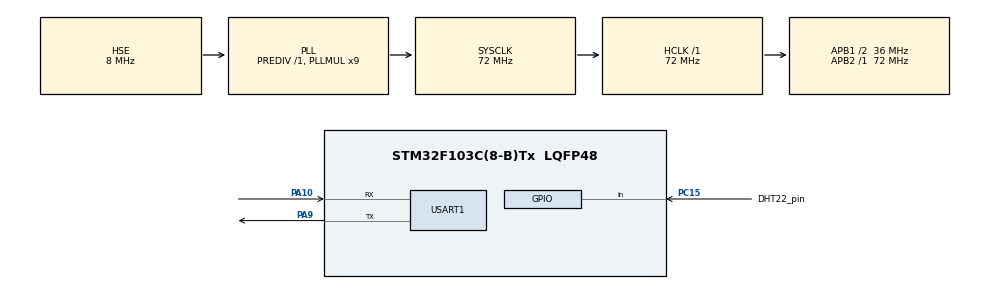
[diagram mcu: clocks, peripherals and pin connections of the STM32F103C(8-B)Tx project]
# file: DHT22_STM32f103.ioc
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Mcu.Family=STM32F1
Mcu.Name=STM32F103C(8-B)Tx
Mcu.Package=LQFP48
NVIC.PriorityGroup=NVIC_PRIORITYGROUP_4
PA10.Mode=Asynchronous
PA10.Signal=USART1_RX
PA13.Mode=Serial_Wire
PA13.Signal=SYS_JTMS-SWDIO
PA14.Mode=Serial_Wire
PA14.Signal=SYS_JTCK-SWCLK
PA9.Mode=Asynchronous
PA9.Signal=USART1_TX
PC15-OSC32_OUT.GPIO_Label=DHT22_pin
PC15-OSC32_OUT.Signal=GPIO_Input
PD0-OSC_IN.Mode=HSE-External-Oscillator
PD0-OSC_IN.Signal=RCC_OSC_IN
PD1-OSC_OUT.Mode=HSE-External-Oscillator
PD1-OSC_OUT.Signal=RCC_OSC_OUT
ProjectManager.HeapSize=0x200
ProjectManager.StackSize=0x400
ProjectManager.TargetToolchain=MDK-ARM V5
RCC.AHBFreq_Value=72000000
RCC.APB1CLKDivider=RCC_HCLK_DIV2
RCC.APB1Freq_Value=36000000
RCC.APB1TimFreq_Value=72000000
RCC.APB2Freq_Value=72000000
RCC.APB2TimFreq_Value=72000000
RCC.HCLKFreq_Value=72000000
RCC.PLLMUL=RCC_PLL_MUL9
RCC.PLLSourceVirtual=RCC_PLLSOURCE_HSE
RCC.SYSCLKFreq_VALUE=72000000
RCC.SYSCLKSource=RCC_SYSCLKSOURCE_PLLCLK
RCC.USBFreq_Value=72000000
TIM1.Period=0xffff
TIM1.Prescaler=72-1
USART1.VirtualMode=VM_ASYNC
VP_TIM1_VS_ClockSourceINT.Mode=Internal
board=custom

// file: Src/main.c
/* USER CODE BEGIN Header */
/**
  ******************************************************************************
  * @file           : main.c
  * @brief          : Main program body
  ******************************************************************************
  ** This notice applies to any and all portions of this file
  * that are not between comment pairs USER CODE BEGIN and
  * USER CODE END. Other portions of this file, whether
  * inserted by the user or by software development tools
  * are owned by their respective copyright owners.
  *
  * COPYRIGHT(c) 2020 STMicroelectronics
  *
  * Redistribution and use in source and binary forms, with or without modification,
  * are permitted provided that the following conditions are met:
  *   1. Redistributions of source code must retain the above copyright notice,
  *      this list of conditions and the following disclaimer.
  *   2. Redistributions in binary form must reproduce the above copyright notice,
  *      this list of conditions and the following disclaimer in the documentation
  *      and/or other materials provided with the distribution.
  *   3. Neither the name of STMicroelectronics nor the names of its contributors
  *      may be used to endorse or promote products derived from this software
  *      without specific prior written permission.
  *
  * THIS SOFTWARE IS PROVIDED BY THE COPYRIGHT HOLDERS AND CONTRIBUTORS "AS IS"
  * AND ANY EXPRESS OR IMPLIED WARRANTIES, INCLUDING, BUT NOT LIMITED TO, THE
  * IMPLIED WARRANTIES OF MERCHANTABILITY AND FITNESS FOR A PARTICULAR PURPOSE ARE
  * DISCLAIMED. IN NO EVENT SHALL THE COPYRIGHT HOLDER OR CONTRIBUTORS BE LIABLE
  * FOR ANY DIRECT, INDIRECT, INCIDENTAL, SPECIAL, EXEMPLARY, OR CONSEQUENTIAL
  * DAMAGES (INCLUDING, BUT NOT LIMITED TO, PROCUREMENT OF SUBSTITUTE GOODS OR
  * SERVICES; LOSS OF USE, DATA, OR PROFITS; OR BUSINESS INTERRUPTION) HOWEVER
  * CAUSED AND ON ANY THEORY OF LIABILITY, WHETHER IN CONTRACT, STRICT LIABILITY,
  * OR TORT (INCLUDING NEGLIGENCE OR OTHERWISE) ARISING IN ANY WAY OUT OF THE USE
  * OF THIS SOFTWARE, EVEN IF ADVISED OF THE POSSIBILITY OF SUCH DAMAGE.
  *
  ******************************************************************************
  */
/* USER CODE END Header */

#include "main.h"

/* USER CODE BEGIN Includes */
//************************************
//			DHT		      	STM32f103
//-------------------------------
//		DATA OUT					PC15
//************************************
//
/* USER CODE END Includes */

TIM_HandleTypeDef htim1;

UART_HandleTypeDef huart1;

void SystemClock_Config(void);
static void MX_GPIO_Init(void);
static void MX_TIM1_Init(void);
static void MX_USART1_UART_Init(void);

/* USER CODE BEGIN 0 */
uint8_t Rh_byte1, Rh_byte2, Temp_byte1, Temp_byte2;
uint16_t sum, RH, TEMP;
uint8_t check = 0;
float t,r;
//**************************************************
char buf_temp[100],buf_humid[100];
//**************************************************

GPIO_InitTypeDef GPIO_InitStruct;

void set_gpio_output (void)
{
	/*Configure GPIO pin output: PA1 */
  GPIO_InitStruct.Pin = DHT22_pin_Pin;
  GPIO_InitStruct.Mode = GPIO_MODE_OUTPUT_PP;
  GPIO_InitStruct.Speed = GPIO_SPEED_FREQ_LOW;
  HAL_GPIO_Init(DHT22_pin_GPIO_Port, &GPIO_InitStruct);
}

void set_gpio_input (void)
{
	/*Configure GPIO pin input: PA1 */
  GPIO_InitStruct.Pin = DHT22_pin_Pin;
  GPIO_InitStruct.Mode = GPIO_MODE_INPUT;
  GPIO_InitStruct.Pull = GPIO_NOPULL;
  HAL_GPIO_Init(DHT22_pin_GPIO_Port, &GPIO_InitStruct);
}

void delay_us (uint16_t us)
{
	__HAL_TIM_SET_COUNTER(&htim1,0);   //set the counter value to zero
	while(__HAL_TIM_GET_COUNTER(&htim1) < us); //wait for the counter to reach the us input in the parameter
}

void DHT22_start (void)
{
	set_gpio_output ();  // set the pin as output
	HAL_GPIO_WritePin (DHT22_pin_GPIO_Port, DHT22_pin_Pin ,GPIO_PIN_RESET);   // pull the pin low
	//delay_us(500);
	delay_us(500);   // wait for 500us
	HAL_GPIO_WritePin (DHT22_pin_GPIO_Port, GPIO_PIN_1,GPIO_PIN_SET);   // pull the pin high
	//delay_us(30);
	delay_us(30);   // wait for 30us
	set_gpio_input ();   // set as input
}

void check_response (void)
{
	delay_us(40);  // wait for 40us
	if (!(HAL_GPIO_ReadPin (DHT22_pin_GPIO_Port, DHT22_pin_Pin))) // if the pin is low
	{

		delay_us(80);   // wait for 80us
		if ((HAL_GPIO_ReadPin (DHT22_pin_GPIO_Port, DHT22_pin_Pin)))  check = 1;  // if the pin is high, response is ok
	}
	while((HAL_GPIO_ReadPin (DHT22_pin_GPIO_Port, DHT22_pin_Pin)));   // wait for the pin to go low
}

uint8_t read_data (void)
{
	uint8_t i,j;
	for (j=0;j<8;j++)
	{
		while (!(HAL_GPIO_ReadPin (DHT22_pin_GPIO_Port, DHT22_pin_Pin)));   // wait for the pin to go high

		delay_us(40);   // wait for 40 us
		if ((HAL_GPIO_ReadPin (DHT22_pin_GPIO_Port, DHT22_pin_Pin)) == 0)   // if the pin is low
		{
			i&= ~(1<<(7-j));   // write 0
		}
		else i|= (1<<(7-j));  // if the pin is high, write 1
		while ((HAL_GPIO_ReadPin (DHT22_pin_GPIO_Port, DHT22_pin_Pin)));  // wait for the pin to go low
	}
	return i;
}
/* USER CODE END 0 */

int main(void)
{

  /* MCU Configuration--------------------------------------------------------*/

  /* Reset of all peripherals, Initializes the Flash interface and the Systick. */
  HAL_Init();

  /* Configure the system clock */
  SystemClock_Config();

  /* Initialize all configured peripherals */
  MX_GPIO_Init();
  MX_TIM1_Init();
  MX_USART1_UART_Init();
  /* USER CODE BEGIN 2 */
	HAL_TIM_Base_Start(&htim1);
	HAL_UART_Transmit(&huart1, (uint8_t *)"STARTING SENSOR READING\r\n",sizeof("STARTING SENSOR READING\r\n"),100);
  /* USER CODE END 2 */

  /* Infinite loop */
  while (1)
  {

    /* USER CODE BEGIN 3 */

		DHT22_start ();
		check_response();

		Rh_byte1 = read_data ();
		Rh_byte2 = read_data ();
		Temp_byte1 = read_data ();
		Temp_byte2 = read_data ();
		sum = read_data();

		TEMP = ((Temp_byte1<<8)|Temp_byte2);
		RH = ((Rh_byte1<<8)|Rh_byte2);

   	t=TEMP*0.1;
	  r=RH*0.1;
		int len = sprintf(buf_temp," Temperature is %.2f And Humidity is %.2f\r\n",t,r);
		HAL_UART_Transmit(&huart1, (uint8_t *)buf_temp,len,100);
		HAL_Delay (500);
  }
  /* USER CODE END 3 */
}

void SystemClock_Config(void)
{
  RCC_OscInitTypeDef RCC_OscInitStruct = {0};
  RCC_ClkInitTypeDef RCC_ClkInitStruct = {0};

  /**Initializes the CPU, AHB and APB busses clocks
  */
  RCC_OscInitStruct.OscillatorType = RCC_OSCILLATORTYPE_HSE;
  RCC_OscInitStruct.HSEState = RCC_HSE_ON;
  RCC_OscInitStruct.HSEPredivValue = RCC_HSE_PREDIV_DIV1;
  RCC_OscInitStruct.HSIState = RCC_HSI_ON;
  RCC_OscInitStruct.PLL.PLLState = RCC_PLL_ON;
  RCC_OscInitStruct.PLL.PLLSource = RCC_PLLSOURCE_HSE;
  RCC_OscInitStruct.PLL.PLLMUL = RCC_PLL_MUL9;
  if (HAL_RCC_OscConfig(&RCC_OscInitStruct) != HAL_OK)
  {
    Error_Handler();
  }
  /**Initializes the CPU, AHB and APB busses clocks
  */
  RCC_ClkInitStruct.ClockType = RCC_CLOCKTYPE_HCLK|RCC_CLOCKTYPE_SYSCLK
                              |RCC_CLOCKTYPE_PCLK1|RCC_CLOCKTYPE_PCLK2;
  RCC_ClkInitStruct.SYSCLKSource = RCC_SYSCLKSOURCE_PLLCLK;
  RCC_ClkInitStruct.AHBCLKDivider = RCC_SYSCLK_DIV1;
  RCC_ClkInitStruct.APB1CLKDivider = RCC_HCLK_DIV2;
  RCC_ClkInitStruct.APB2CLKDivider = RCC_HCLK_DIV1;

  if (HAL_RCC_ClockConfig(&RCC_ClkInitStruct, FLASH_LATENCY_2) != HAL_OK)
  {
    Error_Handler();
  }
}

static void MX_TIM1_Init(void)
{

  TIM_ClockConfigTypeDef sClockSourceConfig = {0};
  TIM_MasterConfigTypeDef sMasterConfig = {0};

  htim1.Instance = TIM1;
  htim1.Init.Prescaler = 72-1;
  htim1.Init.CounterMode = TIM_COUNTERMODE_UP;
  htim1.Init.Period = 0xffff;
  htim1.Init.ClockDivision = TIM_CLOCKDIVISION_DIV1;
  htim1.Init.RepetitionCounter = 0;
  htim1.Init.AutoReloadPreload = TIM_AUTORELOAD_PRELOAD_DISABLE;
  if (HAL_TIM_Base_Init(&htim1) != HAL_OK)
  {
    Error_Handler();
  }
  sClockSourceConfig.ClockSource = TIM_CLOCKSOURCE_INTERNAL;
  if (HAL_TIM_ConfigClockSource(&htim1, &sClockSourceConfig) != HAL_OK)
  {
    Error_Handler();
  }
  sMasterConfig.MasterOutputTrigger = TIM_TRGO_RESET;
  sMasterConfig.MasterSlaveMode = TIM_MASTERSLAVEMODE_DISABLE;
  if (HAL_TIMEx_MasterConfigSynchronization(&htim1, &sMasterConfig) != HAL_OK)
  {
    Error_Handler();
  }

}

static void MX_USART1_UART_Init(void)
{

  huart1.Instance = USART1;
  huart1.Init.BaudRate = 115200;
  huart1.Init.WordLength = UART_WORDLENGTH_8B;
  huart1.Init.StopBits = UART_STOPBITS_1;
  huart1.Init.Parity = UART_PARITY_NONE;
  huart1.Init.Mode = UART_MODE_TX_RX;
  huart1.Init.HwFlowCtl = UART_HWCONTROL_NONE;
  huart1.Init.OverSampling = UART_OVERSAMPLING_16;
  if (HAL_UART_Init(&huart1) != HAL_OK)
  {
    Error_Handler();
  }

}

static void MX_GPIO_Init(void)
{
  GPIO_InitTypeDef GPIO_InitStruct = {0};

  /* GPIO Ports Clock Enable */
  __HAL_RCC_GPIOC_CLK_ENABLE();
  __HAL_RCC_GPIOD_CLK_ENABLE();
  __HAL_RCC_GPIOA_CLK_ENABLE();

  /*Configure GPIO pin : DHT22_pin_Pin */
  GPIO_InitStruct.Pin = DHT22_pin_Pin;
  GPIO_InitStruct.Mode = GPIO_MODE_INPUT;
  GPIO_InitStruct.Pull = GPIO_NOPULL;
  HAL_GPIO_Init(DHT22_pin_GPIO_Port, &GPIO_InitStruct);

}

void Error_Handler(void)
{
}

/************************ (C) COPYRIGHT STMicroelectronics *****END OF FILE****/
